# ATmega324PB device description
Architecture: AVR8; Family: megaAVR
Registers are 8-bit, access not given, no defined reset value unless marked. A register's access mark holds for its fields unless they carry their own. Offsets are from the block's base; [hi:lo] are bit positions.

## USART2 — USART
Instances: USART2 0x00
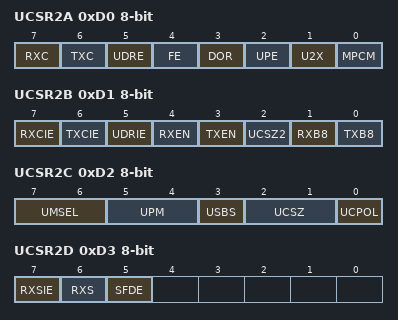
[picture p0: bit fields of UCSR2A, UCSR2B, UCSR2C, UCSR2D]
0xD0 UCSR2A — USART Control and Status Register A
  [7] RXC — USART Receive Complete
  [6] TXC — USART Transmitt Complete
  [5] UDRE — USART Data Register Empty
  [4] FE — Framing Error
  [3] DOR — Data overRun
  [2] UPE — Parity Error
  [1] U2X — Double the USART transmission speed
  [0] MPCM — Multi-processor Communication Mode
0xD1 UCSR2B — USART Control and Status Register B
  [7] RXCIE — RX Complete Interrupt Enable
  [6] TXCIE — TX Complete Interrupt Enable
  [5] UDRIE — USART Data register Empty Interrupt Enable
  [4] RXEN — Receiver Enable
  [3] TXEN — Transmitter Enable
  [2] UCSZ2 — Character Size
  [1] RXB8 — Receive Data Bit 8
  [0] TXB8 — Transmit Data Bit 8
0xD2 UCSR2C — USART Control and Status Register C
  [7:6] UMSEL — USART Mode Select
    0=Asynchronous Operation; 1=Synchronous Operation; 3=Master SPI
  [5:4] UPM — Parity Mode Bits
    0=Disabled; 2=Enabled, Even Parity; 3=Enabled, Odd Parity
  [3] USBS — Stop Bit Select
    0=1-bit; 1=2-bit
  [2:1] UCSZ — Character Size
  [0] UCPOL — Clock Polarity
0xD3 UCSR2D — USART Control and Status Register D
  [7] RXSIE — RX Start Frame Interrupt Enable
  [6] RXS — Start Frame Detect Flag
  [5] SFDE — Start Frame Detection Enable
0xD4 UBRR2 16-bit bits used 11:0 — USART Baud Rate Register Bytes
0xD6 UDR2 — USART I/O Data Register

## PORTA — I/O Port
Instances: PORTA 0x00
0x20 PINA — Port A Input Pins
0x21 DDRA — Port A Data Direction Register
0x22 PORTA — Port A Data Register

## PORTB — I/O Port
Instances: PORTB 0x00
0x23 PINB — Port B Input Pins
0x24 DDRB — Port B Data Direction Register
0x25 PORTB — Port B Data Register

## PORTC — I/O Port
Instances: PORTC 0x00
0x26 PINC — Port C Input Pins
0x27 DDRC — Port C Data Direction Register
0x28 PORTC — Port C Data Register

## PORTD — I/O Port
Instances: PORTD 0x00
0x29 PIND — Port D Input Pins
0x2A DDRD — Port D Data Direction Register
0x2B PORTD — Port D Data Register

## PORTE — I/O Port
Instances: PORTE 0x00
0x2C PINE bits used 6:0 — Port E Input Pins
0x2D DDRE bits used 6:0 — Port E Data Direction Register
0x2E PORTE bits used 6:0 — Port E Data Register

## TC0 (TC8 module) — Timer/Counter, 8-bit
Instances: TC0 0x00
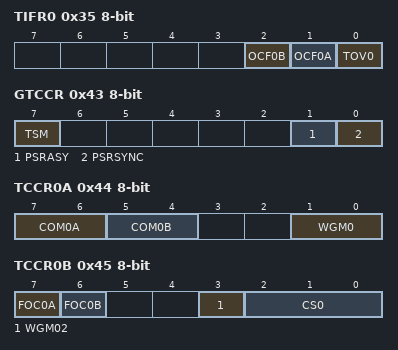
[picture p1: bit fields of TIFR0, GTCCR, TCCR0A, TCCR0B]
0x35 TIFR0 — Timer/Counter0 Interrupt Flag register
  [2] OCF0B — Timer/Counter0 Output Compare Flag 0B
  [1] OCF0A — Timer/Counter0 Output Compare Flag 0A
  [0] TOV0 — Timer/Counter0 Overflow Flag
0x43 GTCCR — General Timer/Counter Control Register
  [7] TSM — Timer/Counter Synchronization Mode
  [1] PSRASY — Prescaler Reset Timer/Counter2
  [0] PSRSYNC — Prescaler Reset Timer/Counter1 and Timer/Counter0
0x44 TCCR0A — Timer/Counter0 Control Register A
  [7:6] COM0A — Compare Match Output A Mode
  [5:4] COM0B — Compare Match Output B Mode
  [1:0] WGM0 — Waveform Generation Mode
0x45 TCCR0B — Timer/Counter0 Control Register B
  [7] FOC0A — Force Output Compare A
  [6] FOC0B — Force Output Compare B
  [3] WGM02 — Waveform Generation Mode
  [2:0] CS0 — Clock Select
    0=No Clock Source (Stopped); 1=Running, No Prescaling; 2=Running, CLK/8; 3=Running, CLK/64; 4=Running, CLK/256; 5=Running, CLK/1024; 6=Running, ExtClk Tx Falling Edge; 7=Running, ExtClk Tx Rising Edge
0x46 TCNT0 — Timer/Counter0
0x47 OCR0A — Timer/Counter0 Output Compare Register
0x48 OCR0B — Timer/Counter0 Output Compare Register
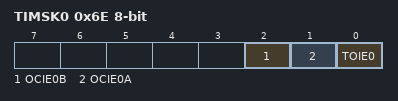
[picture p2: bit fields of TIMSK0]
0x6E TIMSK0 — Timer/Counter0 Interrupt Mask Register
  [2] OCIE0B — Timer/Counter0 Output Compare Match B Interrupt Enable
  [1] OCIE0A — Timer/Counter0 Output Compare Match A Interrupt Enable
  [0] TOIE0 — Timer/Counter0 Overflow Interrupt Enable
